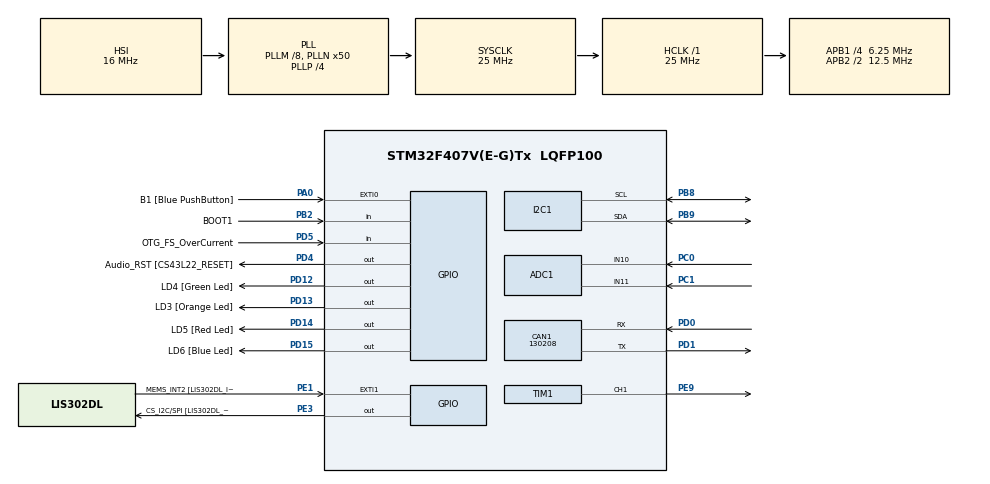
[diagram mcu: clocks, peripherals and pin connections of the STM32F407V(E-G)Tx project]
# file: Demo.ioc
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ADC1.Channel-0\#ChannelRegularConversion=ADC_CHANNEL_10
ADC1.NbrOfConversionFlag=1
ADC1.Rank-0\#ChannelRegularConversion=1
ADC1.SamplingTime-0\#ChannelRegularConversion=ADC_SAMPLETIME_3CYCLES
ADC1.master=1
CAN1.CalculateBaudRate=130208
CAN1.CalculateTimeBit=7680
CAN1.CalculateTimeQuantum=2560.0
Mcu.Family=STM32F4
Mcu.Name=STM32F407V(E-G)Tx
Mcu.Package=LQFP100
NVIC.PriorityGroup=NVIC_PRIORITYGROUP_0
PA0-WKUP.GPIO_Label=B1 [Blue PushButton]
PA0-WKUP.Signal=GPXTI0
PA10.GPIO_Label=OTG_FS_ID
PA10.GPIO_Mode=GPIO_MODE_AF_PP
PA10.GPIO_PuPd=GPIO_NOPULL
PA10.GPIO_Speed=GPIO_SPEED_FREQ_LOW
PA10.Signal=USB_OTG_FS_ID
PA11.GPIO_Label=OTG_FS_DM
PA11.GPIO_Mode=GPIO_MODE_AF_PP
PA11.GPIO_PuPd=GPIO_NOPULL
PA11.GPIO_Speed=GPIO_SPEED_FREQ_LOW
PA11.Signal=USB_OTG_FS_DM
PA12.GPIO_Label=OTG_FS_DP
PA12.GPIO_Mode=GPIO_MODE_AF_PP
PA12.GPIO_PuPd=GPIO_NOPULL
PA12.GPIO_Speed=GPIO_SPEED_FREQ_LOW
PA12.Signal=USB_OTG_FS_DP
PA13.GPIO_Label=SWDIO
PA13.Signal=SYS_JTMS-SWDIO
PA14.GPIO_Label=SWCLK
PA14.Signal=SYS_JTCK-SWCLK
PA4.GPIO_Label=I2S3_WS [CS43L22_LRCK]
PA4.GPIO_Mode=GPIO_MODE_AF_PP
PA4.GPIO_PuPd=GPIO_NOPULL
PA4.GPIO_Speed=GPIO_SPEED_FREQ_LOW
PA4.Signal=I2S3_WS
PA5.GPIO_Label=SPI1_SCK [LIS302DL_SCL/SPC]
PA5.GPIO_Mode=GPIO_MODE_AF_PP
PA5.GPIO_PuPd=GPIO_NOPULL
PA5.GPIO_Speed=GPIO_SPEED_FREQ_LOW
PA5.Signal=SPI1_SCK
PA6.GPIO_Label=SPI1_MISO [LIS302DL_SDO]
PA6.GPIO_Mode=GPIO_MODE_AF_PP
PA6.GPIO_PuPd=GPIO_NOPULL
PA6.GPIO_Speed=GPIO_SPEED_FREQ_LOW
PA6.Signal=SPI1_MISO
PA7.GPIO_Label=SPI1_MOSI [LIS302DL_SDA/SDI/SDO]
PA7.GPIO_Mode=GPIO_MODE_AF_PP
PA7.GPIO_PuPd=GPIO_NOPULL
PA7.GPIO_Speed=GPIO_SPEED_FREQ_LOW
PA7.Signal=SPI1_MOSI
PA9.GPIO_Label=VBUS_FS
PA9.GPIO_Mode=GPIO_MODE_INPUT
PA9.GPIO_PuPd=GPIO_NOPULL
PA9.Signal=USB_OTG_FS_VBUS
PB10.GPIO_Label=CLK_IN [MP45DT02_CLK]
PB10.GPIO_Mode=GPIO_MODE_AF_PP
PB10.GPIO_PuPd=GPIO_NOPULL
PB10.GPIO_Speed=GPIO_SPEED_FREQ_LOW
PB10.Signal=I2S2_CK
PB2.GPIO_Label=BOOT1
PB2.GPIO_Mode=GPIO_MODE_INPUT
PB2.GPIO_PuPd=GPIO_NOPULL
PB2.Signal=GPIO_Input
PB3.GPIO_Label=SWO
PB3.Signal=SYS_JTDO-SWO
PB8.Mode=I2C
PB8.Signal=I2C1_SCL
PB9.Mode=I2C
PB9.Signal=I2C1_SDA
PC0.Signal=ADCx_IN10
PC1.Signal=ADCx_IN11
PC10.GPIO_Label=I2S3_SCK [CS43L22_SCLK]
PC10.GPIO_Mode=GPIO_MODE_AF_PP
PC10.GPIO_PuPd=GPIO_NOPULL
PC10.GPIO_Speed=GPIO_SPEED_FREQ_LOW
PC10.Signal=I2S3_CK
PC12.GPIO_Label=I2S3_SD [CS43L22_SDIN]
PC12.GPIO_Mode=GPIO_MODE_AF_PP
PC12.GPIO_PuPd=GPIO_NOPULL
PC12.GPIO_Speed=GPIO_SPEED_FREQ_LOW
PC12.Signal=I2S3_SD
PC14-OSC32_IN.GPIO_Label=PC14-OSC32_IN
PC14-OSC32_IN.Signal=RCC_OSC32_IN
PC15-OSC32_OUT.GPIO_Label=PC15-OSC32_OUT
PC15-OSC32_OUT.Signal=RCC_OSC32_OUT
PC3.GPIO_Label=PDM_OUT [MP45DT02_DOUT]
PC3.GPIO_Mode=GPIO_MODE_AF_PP
PC3.GPIO_PuPd=GPIO_NOPULL
PC3.GPIO_Speed=GPIO_SPEED_FREQ_LOW
PC3.Signal=I2S2_SD
PC7.GPIO_Label=I2S3_MCK [CS43L22_MCLK]
PC7.GPIO_Mode=GPIO_MODE_AF_PP
PC7.GPIO_PuPd=GPIO_NOPULL
PC7.GPIO_Speed=GPIO_SPEED_FREQ_LOW
PC7.Signal=I2S3_MCK
PD0.Mode=CAN_Activate
PD0.Signal=CAN1_RX
PD1.Mode=CAN_Activate
PD1.Signal=CAN1_TX
PD12.GPIO_Label=LD4 [Green Led]
PD12.GPIO_PuPd=GPIO_NOPULL
PD12.GPIO_Speed=GPIO_SPEED_FREQ_LOW
PD12.Signal=GPIO_Output
PD13.GPIO_Label=LD3 [Orange Led]
PD13.GPIO_PuPd=GPIO_NOPULL
PD13.GPIO_Speed=GPIO_SPEED_FREQ_LOW
PD13.Signal=GPIO_Output
PD14.GPIO_Label=LD5 [Red Led]
PD14.GPIO_PuPd=GPIO_NOPULL
PD14.GPIO_Speed=GPIO_SPEED_FREQ_LOW
PD14.Signal=GPIO_Output
PD15.GPIO_Label=LD6 [Blue Led]
PD15.GPIO_PuPd=GPIO_NOPULL
PD15.GPIO_Speed=GPIO_SPEED_FREQ_LOW
PD15.Signal=GPIO_Output
PD4.GPIO_Label=Audio_RST [CS43L22_RESET]
PD4.GPIO_PuPd=GPIO_NOPULL
PD4.GPIO_Speed=GPIO_SPEED_FREQ_LOW
PD4.Signal=GPIO_Output
PD5.GPIO_Label=OTG_FS_OverCurrent
PD5.GPIO_Mode=GPIO_MODE_INPUT
PD5.GPIO_PuPd=GPIO_NOPULL
PD5.Signal=GPIO_Input
PE1.GPIO_Label=MEMS_INT2 [LIS302DL_INT2]
PE1.GPIO_ModeDefaultEXTI=GPIO_MODE_EVT_RISING
PE1.GPIO_PuPd=GPIO_NOPULL
PE1.Signal=GPXTI1
PE3.GPIO_Label=CS_I2C/SPI [LIS302DL_CS_I2C/SPI]
PE3.GPIO_PuPd=GPIO_NOPULL
PE3.GPIO_Speed=GPIO_SPEED_FREQ_LOW
PE3.Signal=GPIO_Output
PE9.Signal=S_TIM1_CH1
PH0-OSC_IN.GPIO_Label=PH0-OSC_IN
PH0-OSC_IN.Signal=RCC_OSC_IN
PH1-OSC_OUT.GPIO_Label=PH1-OSC_OUT
PH1-OSC_OUT.Signal=RCC_OSC_OUT
ProjectManager.HeapSize=0x200
ProjectManager.StackSize=0x400
ProjectManager.TargetToolchain=STM32CubeIDE
RCC.48MHZClocksFreq_Value=14285714.285714285
RCC.AHBFreq_Value=25000000
RCC.APB1CLKDivider=RCC_HCLK_DIV4
RCC.APB1Freq_Value=6250000
RCC.APB1TimFreq_Value=12500000
RCC.APB2CLKDivider=RCC_HCLK_DIV2
RCC.APB2Freq_Value=12500000
RCC.APB2TimFreq_Value=25000000
RCC.CortexFreq_Value=25000000
RCC.HCLKFreq_Value=25000000
RCC.HSE_VALUE=8000000
RCC.HSI_VALUE=16000000
RCC.LSE_VALUE=32768
RCC.PLLM=8
RCC.PLLN=50
RCC.PLLP=RCC_PLLP_DIV4
RCC.PLLQ=7
RCC.SYSCLKFreq_VALUE=25000000
RCC.SYSCLKSource=RCC_SYSCLKSOURCE_PLLCLK
RCC.VCOOutputFreq_Value=100000000
SH.ADCx_IN10.0=ADC1_IN10,IN10
SH.ADCx_IN11.0=ADC1_IN11,IN11
SH.S_TIM1_CH1.0=TIM1_CH1,PWM Generation1 CH1
TIM1.Channel-PWM\ Generation1\ CH1=TIM_CHANNEL_1
TIM1.Period=100-1
TIM1.Prescaler=25
TIM1.Pulse-PWM\ Generation1\ CH1=50
VP_TIM1_VS_ClockSourceINT.Mode=Internal
board=STM32F407G-DISC1

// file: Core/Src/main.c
/* USER CODE BEGIN Header */
/**
  ******************************************************************************
  * @file           : main.c
  * @brief          : Main program body
  ******************************************************************************
  * @attention
  *
  * Copyright (c) 2023 STMicroelectronics.
  * All rights reserved.
  *
  * This software is licensed under terms that can be found in the LICENSE file
  * in the root directory of this software component.
  * If no LICENSE file comes with this software, it is provided AS-IS.
  *
  ******************************************************************************
  */
/* USER CODE END Header */
#include "veml3328_hardware.h"
#include "veml3328_software.h"

ADC_HandleTypeDef hadc1;

CAN_HandleTypeDef hcan1;

TIM_HandleTypeDef htim1;

void SystemClock_Config(void);
static void MX_GPIO_Init(void);
static void MX_CAN1_Init(void);
static void MX_I2C1_Init(void);
static void MX_ADC1_Init(void);
static void MX_TIM1_Init(void);

/* USER CODE BEGIN 0 */
uint16_t dutyCycle = 50;
/* USER CODE END 0 */

int main(void)
{

  /* MCU Configuration--------------------------------------------------------*/

  /* Reset of all peripherals, Initializes the Flash interface and the Systick. */
  HAL_Init();

  /* Configure the system clock */
  SystemClock_Config();

  /* Initialize all configured peripherals */
  MX_GPIO_Init();
  MX_CAN1_Init();
  MX_I2C1_Init();
  MX_ADC1_Init();
  MX_TIM1_Init();

  HAL_TIM_PWM_Start(&htim1, TIM_CHANNEL_1);
  /*Sensor Init*/
  while (veml3328_init() == 0) {
	  return 0;
  }

  veml3328_config(0000);

  /*read from sensor*/
  while(1){
	htim1.Instance -> CCR1 = dutyCycle;
	veml3328_rd_rgb();
	veml3328_rd_lux();

	if (g_data > 40){
		dutyCycle = 85;
		HAL_Delay(5);
	}

	if (g_data < 30){
		dutyCycle = 15;
		if (dutyCycle == 100) {dutyCycle = 10;}
		HAL_Delay(5);
	}
  }

}

void SystemClock_Config(void)
{
  RCC_OscInitTypeDef RCC_OscInitStruct = {0};
  RCC_ClkInitTypeDef RCC_ClkInitStruct = {0};

  /** Configure the main internal regulator output voltage
  */
  __HAL_RCC_PWR_CLK_ENABLE();
  __HAL_PWR_VOLTAGESCALING_CONFIG(PWR_REGULATOR_VOLTAGE_SCALE1);

  /** Initializes the RCC Oscillators according to the specified parameters
  * in the RCC_OscInitTypeDef structure.
  */
  RCC_OscInitStruct.OscillatorType = RCC_OSCILLATORTYPE_HSI;
  RCC_OscInitStruct.HSIState = RCC_HSI_ON;
  RCC_OscInitStruct.HSICalibrationValue = RCC_HSICALIBRATION_DEFAULT;
  RCC_OscInitStruct.PLL.PLLState = RCC_PLL_ON;
  RCC_OscInitStruct.PLL.PLLSource = RCC_PLLSOURCE_HSI;
  RCC_OscInitStruct.PLL.PLLM = 8;
  RCC_OscInitStruct.PLL.PLLN = 50;
  RCC_OscInitStruct.PLL.PLLP = RCC_PLLP_DIV4;
  RCC_OscInitStruct.PLL.PLLQ = 7;
  if (HAL_RCC_OscConfig(&RCC_OscInitStruct) != HAL_OK)
  {
    Error_Handler();
  }

  /** Initializes the CPU, AHB and APB buses clocks
  */
  RCC_ClkInitStruct.ClockType = RCC_CLOCKTYPE_HCLK|RCC_CLOCKTYPE_SYSCLK
                              |RCC_CLOCKTYPE_PCLK1|RCC_CLOCKTYPE_PCLK2;
  RCC_ClkInitStruct.SYSCLKSource = RCC_SYSCLKSOURCE_PLLCLK;
  RCC_ClkInitStruct.AHBCLKDivider = RCC_SYSCLK_DIV1;
  RCC_ClkInitStruct.APB1CLKDivider = RCC_HCLK_DIV4;
  RCC_ClkInitStruct.APB2CLKDivider = RCC_HCLK_DIV2;

  if (HAL_RCC_ClockConfig(&RCC_ClkInitStruct, FLASH_LATENCY_0) != HAL_OK)
  {
    Error_Handler();
  }
}

static void MX_ADC1_Init(void)
{

  ADC_ChannelConfTypeDef sConfig = {0};

  /** Configure the global features of the ADC (Clock, Resolution, Data Alignment and number of conversion)
  */
  hadc1.Instance = ADC1;
  hadc1.Init.ClockPrescaler = ADC_CLOCK_SYNC_PCLK_DIV2;
  hadc1.Init.Resolution = ADC_RESOLUTION_12B;
  hadc1.Init.ScanConvMode = DISABLE;
  hadc1.Init.ContinuousConvMode = DISABLE;
  hadc1.Init.DiscontinuousConvMode = DISABLE;
  hadc1.Init.ExternalTrigConvEdge = ADC_EXTERNALTRIGCONVEDGE_NONE;
  hadc1.Init.ExternalTrigConv = ADC_SOFTWARE_START;
  hadc1.Init.DataAlign = ADC_DATAALIGN_RIGHT;
  hadc1.Init.NbrOfConversion = 1;
  hadc1.Init.DMAContinuousRequests = DISABLE;
  hadc1.Init.EOCSelection = ADC_EOC_SINGLE_CONV;
  if (HAL_ADC_Init(&hadc1) != HAL_OK)
  {
    Error_Handler();
  }

  /** Configure for the selected ADC regular channel its corresponding rank in the sequencer and its sample time.
  */
  sConfig.Channel = ADC_CHANNEL_10;
  sConfig.Rank = 1;
  sConfig.SamplingTime = ADC_SAMPLETIME_3CYCLES;
  if (HAL_ADC_ConfigChannel(&hadc1, &sConfig) != HAL_OK)
  {
    Error_Handler();
  }

}

static void MX_CAN1_Init(void)
{

  hcan1.Instance = CAN1;
  hcan1.Init.Prescaler = 16;
  hcan1.Init.Mode = CAN_MODE_NORMAL;
  hcan1.Init.SyncJumpWidth = CAN_SJW_1TQ;
  hcan1.Init.TimeSeg1 = CAN_BS1_1TQ;
  hcan1.Init.TimeSeg2 = CAN_BS2_1TQ;
  hcan1.Init.TimeTriggeredMode = DISABLE;
  hcan1.Init.AutoBusOff = DISABLE;
  hcan1.Init.AutoWakeUp = DISABLE;
  hcan1.Init.AutoRetransmission = DISABLE;
  hcan1.Init.ReceiveFifoLocked = DISABLE;
  hcan1.Init.TransmitFifoPriority = DISABLE;
  if (HAL_CAN_Init(&hcan1) != HAL_OK)
  {
    Error_Handler();
  }

}

static void MX_I2C1_Init(void)
{

  hi2c1.Instance = I2C1;
  hi2c1.Init.ClockSpeed = 100000;
  hi2c1.Init.DutyCycle = I2C_DUTYCYCLE_2;
  hi2c1.Init.OwnAddress1 = 0;
  hi2c1.Init.AddressingMode = I2C_ADDRESSINGMODE_7BIT;
  hi2c1.Init.DualAddressMode = I2C_DUALADDRESS_DISABLE;
  hi2c1.Init.OwnAddress2 = 0;
  hi2c1.Init.GeneralCallMode = I2C_GENERALCALL_DISABLE;
  hi2c1.Init.NoStretchMode = I2C_NOSTRETCH_DISABLE;
  if (HAL_I2C_Init(&hi2c1) != HAL_OK)
  {
    Error_Handler();
  }

}

static void MX_TIM1_Init(void)
{

  TIM_ClockConfigTypeDef sClockSourceConfig = {0};
  TIM_MasterConfigTypeDef sMasterConfig = {0};
  TIM_OC_InitTypeDef sConfigOC = {0};
  TIM_BreakDeadTimeConfigTypeDef sBreakDeadTimeConfig = {0};

  htim1.Instance = TIM1;
  htim1.Init.Prescaler = 25;
  htim1.Init.CounterMode = TIM_COUNTERMODE_UP;
  htim1.Init.Period = 100-1;
  htim1.Init.ClockDivision = TIM_CLOCKDIVISION_DIV1;
  htim1.Init.RepetitionCounter = 0;
  htim1.Init.AutoReloadPreload = TIM_AUTORELOAD_PRELOAD_DISABLE;
  if (HAL_TIM_Base_Init(&htim1) != HAL_OK)
  {
    Error_Handler();
  }
  sClockSourceConfig.ClockSource = TIM_CLOCKSOURCE_INTERNAL;
  if (HAL_TIM_ConfigClockSource(&htim1, &sClockSourceConfig) != HAL_OK)
  {
    Error_Handler();
  }
  if (HAL_TIM_PWM_Init(&htim1) != HAL_OK)
  {
    Error_Handler();
  }
  sMasterConfig.MasterOutputTrigger = TIM_TRGO_RESET;
  sMasterConfig.MasterSlaveMode = TIM_MASTERSLAVEMODE_DISABLE;
  if (HAL_TIMEx_MasterConfigSynchronization(&htim1, &sMasterConfig) != HAL_OK)
  {
    Error_Handler();
  }
  sConfigOC.OCMode = TIM_OCMODE_PWM1;
  sConfigOC.Pulse = 50;
  sConfigOC.OCPolarity = TIM_OCPOLARITY_HIGH;
  sConfigOC.OCNPolarity = TIM_OCNPOLARITY_HIGH;
  sConfigOC.OCFastMode = TIM_OCFAST_DISABLE;
  sConfigOC.OCIdleState = TIM_OCIDLESTATE_RESET;
  sConfigOC.OCNIdleState = TIM_OCNIDLESTATE_RESET;
  if (HAL_TIM_PWM_ConfigChannel(&htim1, &sConfigOC, TIM_CHANNEL_1) != HAL_OK)
  {
    Error_Handler();
  }
  sBreakDeadTimeConfig.OffStateRunMode = TIM_OSSR_DISABLE;
  sBreakDeadTimeConfig.OffStateIDLEMode = TIM_OSSI_DISABLE;
  sBreakDeadTimeConfig.LockLevel = TIM_LOCKLEVEL_OFF;
  sBreakDeadTimeConfig.DeadTime = 0;
  sBreakDeadTimeConfig.BreakState = TIM_BREAK_DISABLE;
  sBreakDeadTimeConfig.BreakPolarity = TIM_BREAKPOLARITY_HIGH;
  sBreakDeadTimeConfig.AutomaticOutput = TIM_AUTOMATICOUTPUT_DISABLE;
  if (HAL_TIMEx_ConfigBreakDeadTime(&htim1, &sBreakDeadTimeConfig) != HAL_OK)
  {
    Error_Handler();
  }
  HAL_TIM_MspPostInit(&htim1);

}

static void MX_GPIO_Init(void)
{
  GPIO_InitTypeDef GPIO_InitStruct = {0};

  /* GPIO Ports Clock Enable */
  __HAL_RCC_GPIOE_CLK_ENABLE();
  __HAL_RCC_GPIOC_CLK_ENABLE();
  __HAL_RCC_GPIOH_CLK_ENABLE();
  __HAL_RCC_GPIOA_CLK_ENABLE();
  __HAL_RCC_GPIOB_CLK_ENABLE();
  __HAL_RCC_GPIOD_CLK_ENABLE();

  /*Configure GPIO pin Output Level */
  HAL_GPIO_WritePin(CS_I2C_SPI_GPIO_Port, CS_I2C_SPI_Pin, GPIO_PIN_RESET);

  /*Configure GPIO pin Output Level */
  HAL_GPIO_WritePin(GPIOD, LD4_Pin|LD3_Pin|LD5_Pin|LD6_Pin
                          |Audio_RST_Pin, GPIO_PIN_RESET);

  /*Configure GPIO pin : CS_I2C_SPI_Pin */
  GPIO_InitStruct.Pin = CS_I2C_SPI_Pin;
  GPIO_InitStruct.Mode = GPIO_MODE_OUTPUT_PP;
  GPIO_InitStruct.Pull = GPIO_NOPULL;
  GPIO_InitStruct.Speed = GPIO_SPEED_FREQ_LOW;
  HAL_GPIO_Init(CS_I2C_SPI_GPIO_Port, &GPIO_InitStruct);

  /*Configure GPIO pin : PDM_OUT_Pin */
  GPIO_InitStruct.Pin = PDM_OUT_Pin;
  GPIO_InitStruct.Mode = GPIO_MODE_AF_PP;
  GPIO_InitStruct.Pull = GPIO_NOPULL;
  GPIO_InitStruct.Speed = GPIO_SPEED_FREQ_LOW;
  GPIO_InitStruct.Alternate = GPIO_AF5_SPI2;
  HAL_GPIO_Init(PDM_OUT_GPIO_Port, &GPIO_InitStruct);

  /*Configure GPIO pin : B1_Pin */
  GPIO_InitStruct.Pin = B1_Pin;
  GPIO_InitStruct.Mode = GPIO_MODE_IT_RISING;
  GPIO_InitStruct.Pull = GPIO_NOPULL;
  HAL_GPIO_Init(B1_GPIO_Port, &GPIO_InitStruct);

  /*Configure GPIO pin : I2S3_WS_Pin */
  GPIO_InitStruct.Pin = I2S3_WS_Pin;
  GPIO_InitStruct.Mode = GPIO_MODE_AF_PP;
  GPIO_InitStruct.Pull = GPIO_NOPULL;
  GPIO_InitStruct.Speed = GPIO_SPEED_FREQ_LOW;
  GPIO_InitStruct.Alternate = GPIO_AF6_SPI3;
  HAL_GPIO_Init(I2S3_WS_GPIO_Port, &GPIO_InitStruct);

  /*Configure GPIO pins : SPI1_SCK_Pin SPI1_MISO_Pin SPI1_MOSI_Pin */
  GPIO_InitStruct.Pin = SPI1_SCK_Pin|SPI1_MISO_Pin|SPI1_MOSI_Pin;
  GPIO_InitStruct.Mode = GPIO_MODE_AF_PP;
  GPIO_InitStruct.Pull = GPIO_NOPULL;
  GPIO_InitStruct.Speed = GPIO_SPEED_FREQ_LOW;
  GPIO_InitStruct.Alternate = GPIO_AF5_SPI1;
  HAL_GPIO_Init(GPIOA, &GPIO_InitStruct);

  /*Configure GPIO pin : BOOT1_Pin */
  GPIO_InitStruct.Pin = BOOT1_Pin;
  GPIO_InitStruct.Mode = GPIO_MODE_INPUT;
  GPIO_InitStruct.Pull = GPIO_NOPULL;
  HAL_GPIO_Init(BOOT1_GPIO_Port, &GPIO_InitStruct);

  /*Configure GPIO pin : CLK_IN_Pin */
  GPIO_InitStruct.Pin = CLK_IN_Pin;
  GPIO_InitStruct.Mode = GPIO_MODE_AF_PP;
  GPIO_InitStruct.Pull = GPIO_NOPULL;
  GPIO_InitStruct.Speed = GPIO_SPEED_FREQ_LOW;
  GPIO_InitStruct.Alternate = GPIO_AF5_SPI2;
  HAL_GPIO_Init(CLK_IN_GPIO_Port, &GPIO_InitStruct);

  /*Configure GPIO pins : LD4_Pin LD3_Pin LD5_Pin LD6_Pin
                           Audio_RST_Pin */
  GPIO_InitStruct.Pin = LD4_Pin|LD3_Pin|LD5_Pin|LD6_Pin
                          |Audio_RST_Pin;
  GPIO_InitStruct.Mode = GPIO_MODE_OUTPUT_PP;
  GPIO_InitStruct.Pull = GPIO_NOPULL;
  GPIO_InitStruct.Speed = GPIO_SPEED_FREQ_LOW;
  HAL_GPIO_Init(GPIOD, &GPIO_InitStruct);

  /*Configure GPIO pins : I2S3_MCK_Pin I2S3_SCK_Pin I2S3_SD_Pin */
  GPIO_InitStruct.Pin = I2S3_MCK_Pin|I2S3_SCK_Pin|I2S3_SD_Pin;
  GPIO_InitStruct.Mode = GPIO_MODE_AF_PP;
  GPIO_InitStruct.Pull = GPIO_NOPULL;
  GPIO_InitStruct.Speed = GPIO_SPEED_FREQ_LOW;
  GPIO_InitStruct.Alternate = GPIO_AF6_SPI3;
  HAL_GPIO_Init(GPIOC, &GPIO_InitStruct);

  /*Configure GPIO pin : VBUS_FS_Pin */
  GPIO_InitStruct.Pin = VBUS_FS_Pin;
  GPIO_InitStruct.Mode = GPIO_MODE_INPUT;
  GPIO_InitStruct.Pull = GPIO_NOPULL;
  HAL_GPIO_Init(VBUS_FS_GPIO_Port, &GPIO_InitStruct);

  /*Configure GPIO pins : OTG_FS_ID_Pin OTG_FS_DM_Pin OTG_FS_DP_Pin */
  GPIO_InitStruct.Pin = OTG_FS_ID_Pin|OTG_FS_DM_Pin|OTG_FS_DP_Pin;
  GPIO_InitStruct.Mode = GPIO_MODE_AF_PP;
  GPIO_InitStruct.Pull = GPIO_NOPULL;
  GPIO_InitStruct.Speed = GPIO_SPEED_FREQ_LOW;
  GPIO_InitStruct.Alternate = GPIO_AF10_OTG_FS;
  HAL_GPIO_Init(GPIOA, &GPIO_InitStruct);

  /*Configure GPIO pin : OTG_FS_OverCurrent_Pin */
  GPIO_InitStruct.Pin = OTG_FS_OverCurrent_Pin;
  GPIO_InitStruct.Mode = GPIO_MODE_INPUT;
  GPIO_InitStruct.Pull = GPIO_NOPULL;
  HAL_GPIO_Init(OTG_FS_OverCurrent_GPIO_Port, &GPIO_InitStruct);

  /*Configure GPIO pin : MEMS_INT2_Pin */
  GPIO_InitStruct.Pin = MEMS_INT2_Pin;
  GPIO_InitStruct.Mode = GPIO_MODE_EVT_RISING;
  GPIO_InitStruct.Pull = GPIO_NOPULL;
  HAL_GPIO_Init(MEMS_INT2_GPIO_Port, &GPIO_InitStruct);

}

void Error_Handler(void)
{
  __disable_irq();
  while (1)
  {
  }
}
